# EFR32ZG23A020F512GM40 register map
Vendor: Silicon Labs; Series: EFR32; File version: B
Registers are 32-bit, read-write, reset 0x0 unless marked. A register's access mark holds for its fields unless they carry their own. Offsets are from the block's base; [hi:lo] are bit positions; {n}, {i} and the like mark numbered series; 'fields as' and 'values as' point back to an identical list.

## AGC_S — AGC_S Registers
Base 0xA800C000
Same registers: AGC_NS 0xB800C000
0x00 IPVERSION ro reset 0x2
0x04 EN
  [0] EN — Enable peripheral clock to this module
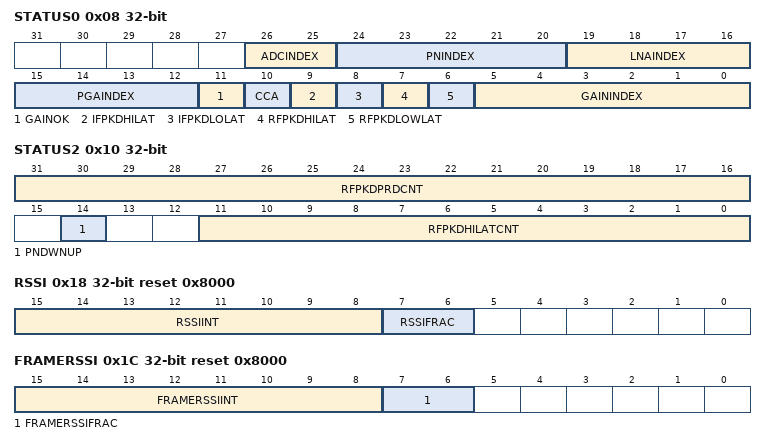
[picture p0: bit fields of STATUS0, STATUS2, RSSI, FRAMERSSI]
0x08 STATUS0 ro
  [26:25] ADCINDEX — ADC Attenuator INDEX
  [24:20] PNINDEX — PN GAIN INDEX
  [19:16] LNAINDEX — LNA GAIN INDEX
  [15:12] PGAINDEX — PGA GAIN INDEX
  [11] GAINOK
  [10] CCA — Clear Channel Assessment
  [9] IFPKDHILAT — IFPKD Hi threshold pass Latch
  [8] IFPKDLOLAT — IFPKD Lo threshold pass Latch
  [7] RFPKDHILAT — RFPKD hi Latch
  [6] RFPKDLOWLAT — RFPKD low Latch
  [5:0] GAININDEX — Gain Table Index
0x0C STATUS1 ro
  [29:18] RFPKDLOWLATCNT — RF PKD Low Latch CNT
0x10 STATUS2 ro
  [31:16] RFPKDPRDCNT — RF PKD PERIOD CNT
  [14] PNDWNUP — Allow PN GAIN UP
  [11:0] RFPKDHILATCNT — RF PKD HI Latch CNT
0x18 RSSI ro reset 0x8000
  [15:8] RSSIINT — RSSI integer part
  [7:6] RSSIFRAC — RSSI fractional part
0x1C FRAMERSSI ro reset 0x8000
  [15:8] FRAMERSSIINT — FRAMERSSI integer part
  [7:6] FRAMERSSIFRAC — FRAMERSSI fractional part
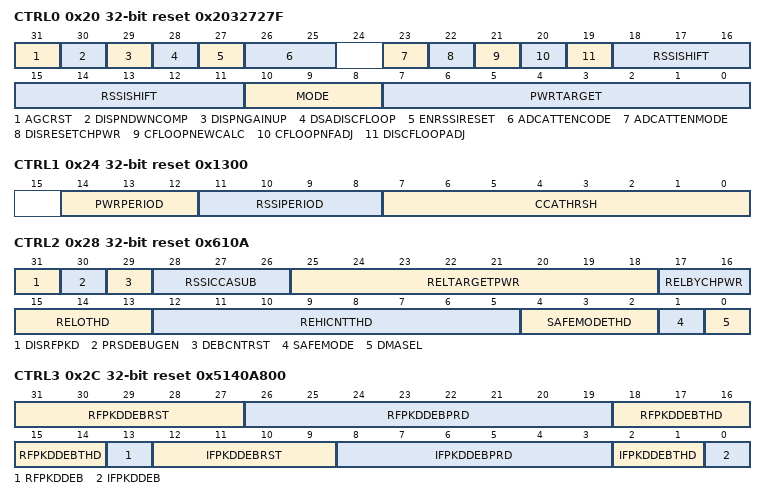
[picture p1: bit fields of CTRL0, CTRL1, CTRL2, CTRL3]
0x20 CTRL0 reset 0x2032727F
  [31] AGCRST — AGC reset
  [30] DISPNDWNCOMP — Disable PN gain decrease compensation
  [29] DISPNGAINUP — Disable PN gain increase
  [28] DSADISCFLOOP — Disable channel filter loop
  [27] ENRSSIRESET — Enables reset of RSSI and CCA
  [26:25] ADCATTENCODE — ADC Attenuator code
  [23] ADCATTENMODE — ADC Attenuator mode
    0=DISABLE (ADC attenuator back-off will not be done by AGC); 1=NOTMAXGAIN (ADC attenuator is backed-off if rxgain is NOT MAXGAIN)
  [22] DISRESETCHPWR — Disable Reset of CHPWR
  [21] CFLOOPNEWCALC — Enable new wanted gain calculation in SL
  [20] CFLOOPNFADJ — Enable NF correction term in SL
  [19] DISCFLOOPADJ — Disable gain adjustment by CFLOOP
  [18:11] RSSISHIFT
  [10:8] MODE
    0=CONT (AGC loop is adjusting gain continuously.); 1=LOCKPREDET (Gain is locked once a preamble is detected.); 2=LOCKFRAMEDET (Gain is locked once a sync word is detected.); 3=LOCKDSA (Gain is locked once DSA is detected.)
  [7:0] PWRTARGET — Power Target
0x24 CTRL1 reset 0x1300
  [14:12] PWRPERIOD — AGC measure period
  [11:8] RSSIPERIOD — RSSI measure period
  [7:0] CCATHRSH — Clear Channel Assessment (CCA) Threshold
0x28 CTRL2 reset 0x610A
  [31] DISRFPKD — Disable RF PEAKDET
  [30] PRSDEBUGEN — PRS Debug Enable
  [29] DEBCNTRST — Debonce CNT Reset MODE
  [28:26] RSSICCASUB — RSSI CCA sub windows
  [25:18] RELTARGETPWR — Safe Mode Release Power Target
  [17:16] RELBYCHPWR — Safe mode release mode
    0=LO_CNT (Increment counter if IFPKD_LO_LAT signal is not set.); 1=PWR (Increment counter if channel power is below RELTARGETPWR.); 2=LO_CNT_PWR (Increment if either LO_CNT or PWR.); 3=LO_CNT_AND_PWR (Increment if both LO_CNT and PWR.)
  [15:13] RELOTHD — Exit threshold based on Release Counter
  [12:5] REHICNTTHD — Exit threshold based on HICNT
  [4:2] SAFEMODETHD — Enter threshold
  [1] SAFEMODE — AGC safe mode
  [0] DMASEL — DMA select
    0=RSSI; 1=GAIN
0x2C CTRL3 reset 0x5140A800
  [31:27] RFPKDDEBRST — RFPKD_LAT debounce reset delay
  [26:19] RFPKDDEBPRD — RF PEAKDET debance period
  [18:14] RFPKDDEBTHD — RF PEAKDET debance thrshold
  [13] RFPKDDEB — RF PEAKDET debounce mode enable
  [12:9] IFPKDDEBRST — IF PEAKDET debounce period
  [8:3] IFPKDDEBPRD — IF PEAKDET debance period
  [2:1] IFPKDDEBTHD — IF PEAKDET debance thrshold
  [0] IFPKDDEB — IF PEAKDET debounce mode enable
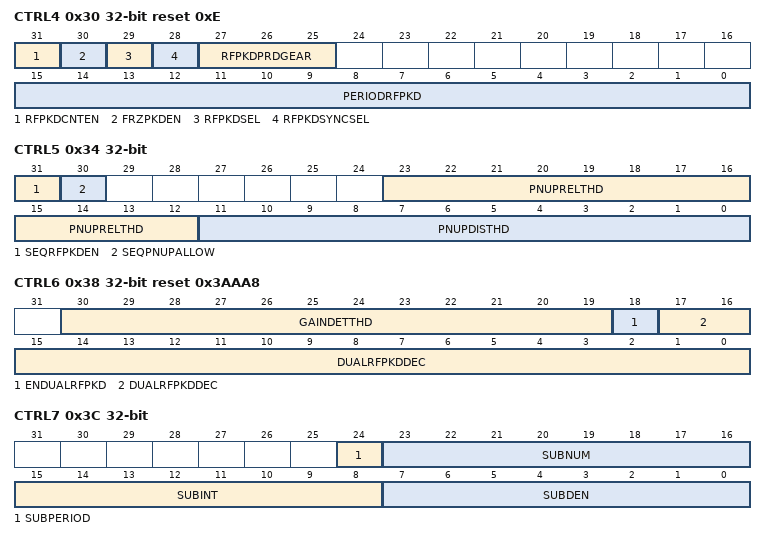
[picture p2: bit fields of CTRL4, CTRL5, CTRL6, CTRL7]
0x30 CTRL4 reset 0xE
  [31] RFPKDCNTEN — Counter-based RFPKD Enable
  [30] FRZPKDEN — PKD Freeze Enable
  [29] RFPKDSEL — RF PKD OUTPUT SELECT
  [28] RFPKDSYNCSEL — SYNC RF PKD OUTPUT SELECT
  [27:25] RFPKDPRDGEAR — RFPKD Period Gear
  [15:0] PERIODRFPKD — RFPKD trigger measure period
0x34 CTRL5
  [31] SEQRFPKDEN — SEQ-based RFPKD Enable
  [30] SEQPNUPALLOW — SEQ Set PN GAIN UP ALLOW
  [23:12] PNUPRELTHD — Enable PN GAIN increase THD
  [11:0] PNUPDISTHD — Disable PN GAIN increase THD
0x38 CTRL6 reset 0x3AAA8
  [30:19] GAINDETTHD — Threshold for gain aligned interrupt
  [18] ENDUALRFPKD — Enable dual RFPKD
  [17:0] DUALRFPKDDEC — Decoding matrix for dualrfpkd logic
0x3C CTRL7
  [24] SUBPERIOD
  [23:16] SUBNUM — Subperiod numerator
  [15:8] SUBINT — Subperiod integer
  [7:0] SUBDEN — Subperiod denominator
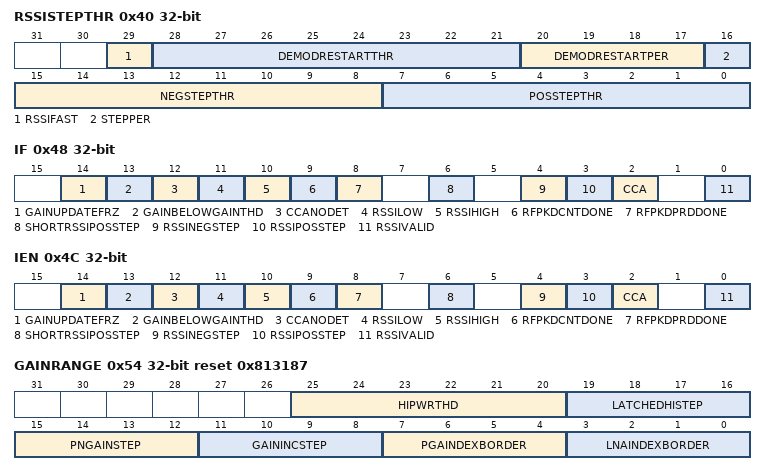
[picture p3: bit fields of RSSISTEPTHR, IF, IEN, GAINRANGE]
0x40 RSSISTEPTHR
  [29] RSSIFAST — RSSI fast startup
  [28:21] DEMODRESTARTTHR — Demodulator Restart Threshold
  [20:17] DEMODRESTARTPER — Demodulator Restart Period
  [16] STEPPER — Step Period
  [15:8] NEGSTEPTHR — Negative Step Threshold
  [7:0] POSSTEPTHR — Positive Step Threshold
0x48 IF
  [14] GAINUPDATEFRZ — AGC gain update frozen int
  [13] GAINBELOWGAINTHD — agc gain above threshold int
  [12] CCANODET — CCA Not Detected
  [11] RSSILOW — RSSI low detected
  [10] RSSIHIGH — RSSI high detected
  [9] RFPKDCNTDONE — RF PKD pulse CNT TOMEOUT
  [8] RFPKDPRDDONE — RF PKD PERIOD CNT TOMEOUT
  [6] SHORTRSSIPOSSTEP — Short-term Positive RSSI Step Detected
  [4] RSSINEGSTEP — Negative RSSI Step Detected
  [3] RSSIPOSSTEP — Positive RSSI Step Detected
  [2] CCA — Clear Channel Assessment
  [0] RSSIVALID — RSSI Value is Valid
0x4C IEN
  [14] GAINUPDATEFRZ — AGC gain update frozen int Enable
  [13] GAINBELOWGAINTHD — GAINBELOWGAINTHD Interrupt Enable
  [12] CCANODET — CCANODET Interrupt Enable
  [11] RSSILOW — RSSILOW Interrupt Enable
  [10] RSSIHIGH — RSSIHIGH Interrupt Enable
  [9] RFPKDCNTDONE — RF PKD pulse CNT Interrupt Enable
  [8] RFPKDPRDDONE — RF PKD PERIOD CNT Interrupt Enable
  [6] SHORTRSSIPOSSTEP — SHORTRSSIPOSSTEP Interrupt Enable
  [4] RSSINEGSTEP — RSSINEGSTEP Interrupt Enable
  [3] RSSIPOSSTEP — RSSIPOSSTEP Interrupt Enable
  [2] CCA — CCA Interrupt Enable
  [0] RSSIVALID — RSSIVALID Interrupt Enable
0x54 GAINRANGE reset 0x813187
  [25:20] HIPWRTHD — High power detect thrshold
  [19:16] LATCHEDHISTEP — Ltached Hi step size
  [15:12] PNGAINSTEP — PN Gain Step size
  [11:8] GAININCSTEP — AGC gain increase step size
  [7:4] PGAINDEXBORDER — PGA gain border
  [3:0] LNAINDEXBORDER — LNA gain border
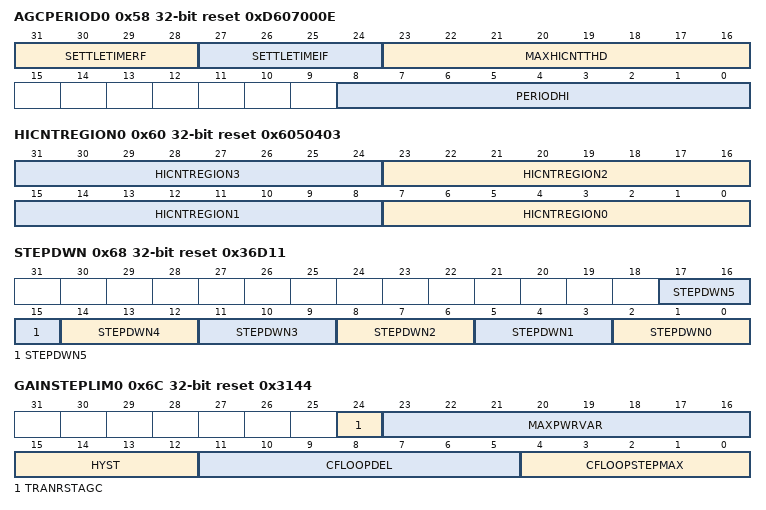
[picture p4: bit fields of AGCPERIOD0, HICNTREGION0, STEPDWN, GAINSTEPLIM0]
0x58 AGCPERIOD0 reset 0xD607000E
  [31:28] SETTLETIMERF — RF peak Detector settling time
  [27:24] SETTLETIMEIF — IF peak Detector settling time
  [23:16] MAXHICNTTHD — max hi-countrer threshold
  [8:0] PERIODHI — AGC measure period hi
0x5C AGCPERIOD1 reset 0x37
  [31:0] PERIODLOW — AGC IF period low th
0x60 HICNTREGION0 reset 0x6050403
  [8n+7:8n] HICNTREGION{n} (n=0..3) — AGC HICNT to step size map region {n}
0x64 HICNTREGION1 reset 0x8
  [7:0] HICNTREGION4 — AGC HICNT to step size map region 4
0x68 STEPDWN reset 0x36D11
  [3n+2:3n] STEPDWN{n} (n=0..5) — AGC gain step size {n}
0x6C GAINSTEPLIM0 reset 0x3144
  [24] TRANRSTAGC — power transient detector Reset AGC
  [23:16] MAXPWRVAR — Maximum Power Variation
  [15:12] HYST — Hysteresis
  [11:5] CFLOOPDEL — Channel Filter Loop Delay
  [4:0] CFLOOPSTEPMAX — Maximum step in slow loop
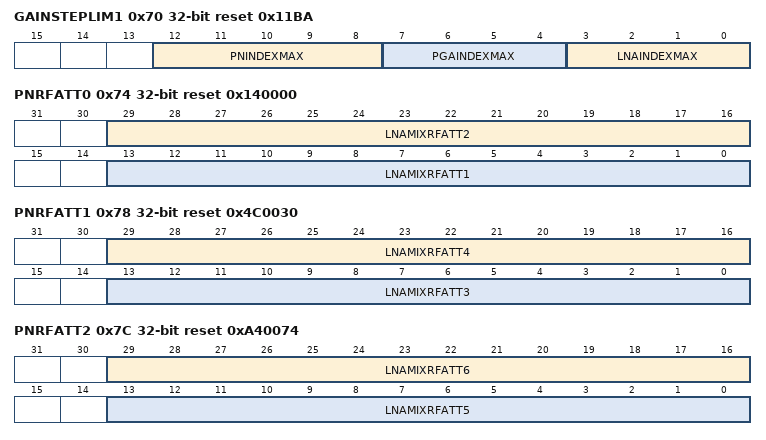
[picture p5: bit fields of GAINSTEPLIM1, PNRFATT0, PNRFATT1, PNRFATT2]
0x70 GAINSTEPLIM1 reset 0x11BA
  [12:8] PNINDEXMAX — MAX PN INDEX
  [7:4] PGAINDEXMAX — MAX LNA INDEX
  [3:0] LNAINDEXMAX — MAX LNA INDEX
0x74 PNRFATT0 reset 0x140000
  [29:16] LNAMIXRFATT2 — PN RF attenuation code for index 2
  [13:0] LNAMIXRFATT1 — PN RF attenuation code for index 1
0x78 PNRFATT1 reset 0x4C0030
  [29:16] LNAMIXRFATT4 — PN RF attenuation code for index 4
  [13:0] LNAMIXRFATT3 — PN RF attenuation code for index 3
0x7C PNRFATT2 reset 0xA40074
  [29:16] LNAMIXRFATT6 — PN RF attenuation code for index 6
  [13:0] LNAMIXRFATT5 — PN RF attenuation code for index 5
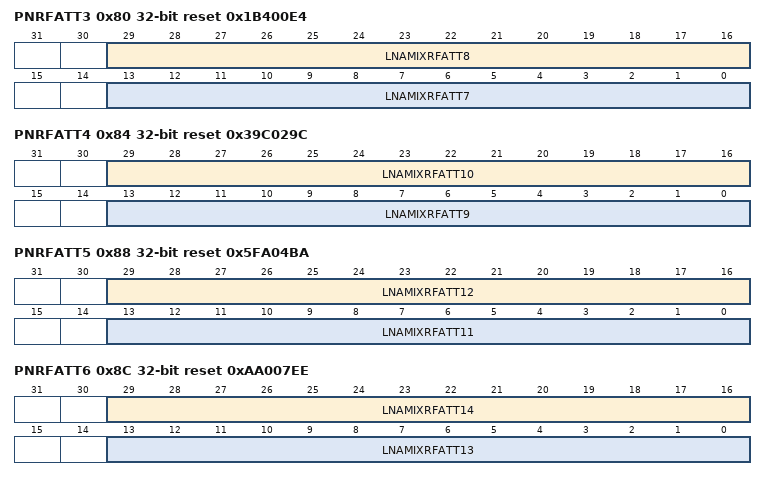
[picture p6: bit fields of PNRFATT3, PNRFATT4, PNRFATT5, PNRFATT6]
0x80 PNRFATT3 reset 0x1B400E4
  [29:16] LNAMIXRFATT8 — PN RF attenuation code for index 8
  [13:0] LNAMIXRFATT7 — PN RF attenuation code for index 7
0x84 PNRFATT4 reset 0x39C029C
  [29:16] LNAMIXRFATT10 — PN RF attenuation code for index 10
  [13:0] LNAMIXRFATT9 — PN RF attenuation code for index 9
0x88 PNRFATT5 reset 0x5FA04BA
  [29:16] LNAMIXRFATT12 — PN RF attenuation code for index 12
  [13:0] LNAMIXRFATT11 — PN RF attenuation code for index 11
0x8C PNRFATT6 reset 0xAA007EE
  [29:16] LNAMIXRFATT14 — PN RF attenuation code for index 14
  [13:0] LNAMIXRFATT13 — PN RF attenuation code for index 13
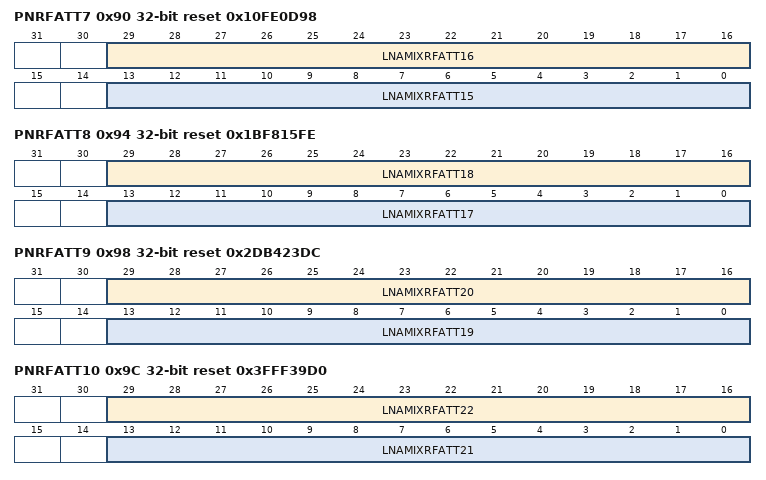
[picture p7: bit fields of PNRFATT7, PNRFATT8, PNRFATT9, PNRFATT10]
0x90 PNRFATT7 reset 0x10FE0D98
  [29:16] LNAMIXRFATT16 — PN RF attenuation code for index 16
  [13:0] LNAMIXRFATT15 — PN RF attenuation code for index 15
0x94 PNRFATT8 reset 0x1BF815FE
  [29:16] LNAMIXRFATT18 — PN RF attenuation code for index 18
  [13:0] LNAMIXRFATT17 — PN RF attenuation code for index 17
0x98 PNRFATT9 reset 0x2DB423DC
  [29:16] LNAMIXRFATT20 — PN RF attenuation code for index 20
  [13:0] LNAMIXRFATT19 — PN RF attenuation code for index 19
0x9C PNRFATT10 reset 0x3FFF39D0
  [29:16] LNAMIXRFATT22 — PN RF attenuation code for index 22
  [13:0] LNAMIXRFATT21 — PN RF attenuation code for index 21
0xA0 PNRFATT11 reset 0x3FFF
  [13:0] LNAMIXRFATT23 — PN RF attenuation code for index 23
0xA4 PNRFATTALT reset 0x3FFF
  [13:0] LNAMIXRFATTALT — PN RF attenuation code for index 21
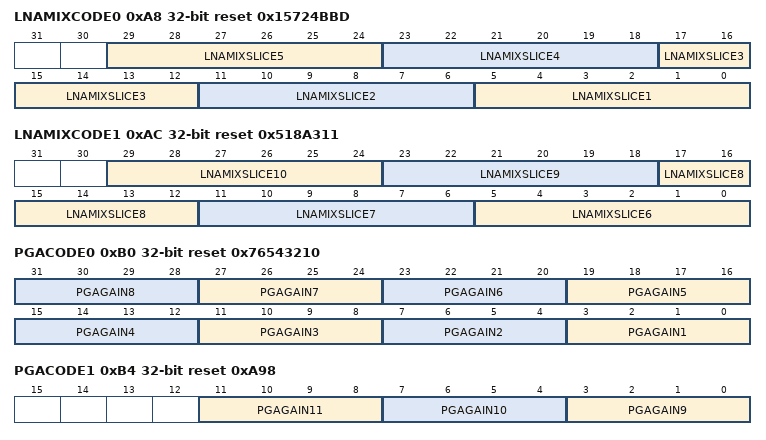
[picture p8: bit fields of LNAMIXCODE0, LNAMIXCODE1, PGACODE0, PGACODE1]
0xA8 LNAMIXCODE0 reset 0x15724BBD
  [6n-1:6n-6] LNAMIXSLICE{n} (n=1..5) — LNA/MIX slice code for index {n}
0xAC LNAMIXCODE1 reset 0x518A311
  [6n-31:6n-36] LNAMIXSLICE{n} (n=6..10) — LNA/MIX slice code for index {n}
0xB0 PGACODE0 reset 0x76543210
  [4n-1:4n-4] PGAGAIN{n} (n=1..8) — PGA GAIN code for index {n}
0xB4 PGACODE1 reset 0xA98
  [11:8] PGAGAIN11 — PGA GAIN code for index 11
  [7:4] PGAGAIN10 — PGA GAIN code for index 10
  [3:0] PGAGAIN9 — PGA GAIN code for index 9
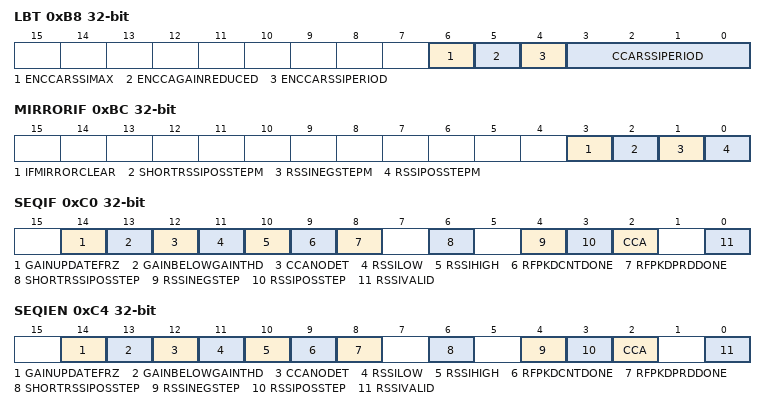
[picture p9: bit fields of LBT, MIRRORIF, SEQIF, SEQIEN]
0xB8 LBT
  [6] ENCCARSSIMAX — Use RSSIMAX to indicate CCA
  [5] ENCCAGAINREDUCED — CCA gain reduced
  [4] ENCCARSSIPERIOD — RSSI PERIOD during CCA measurements
  [3:0] CCARSSIPERIOD — RSSI Period during CCA measurements
0xBC MIRRORIF
  [3] IFMIRRORCLEAR — Clear bit for the AGC IF MIRROR Register
  [2] SHORTRSSIPOSSTEPM ro — Short-term Positive RSSI Step Detected
  [1] RSSINEGSTEPM ro — Negative RSSI Step Detected
  [0] RSSIPOSSTEPM ro — Positive RSSI Step Detected
0xC0 SEQIF
  fields as IF
0xC4 SEQIEN
  fields as IEN
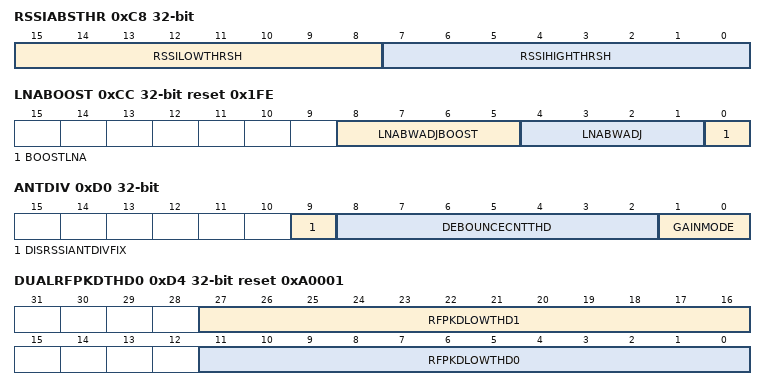
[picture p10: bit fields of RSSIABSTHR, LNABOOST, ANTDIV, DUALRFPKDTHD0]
0xC8 RSSIABSTHR
  [15:8] RSSILOWTHRSH — RSSI Low Threshold
  [7:0] RSSIHIGHTHRSH — RSSI High Threshold
0xCC LNABOOST reset 0x1FE
  [8:5] LNABWADJBOOST — LNA BW ADJUST
  [4:1] LNABWADJ — LNA BW ADJUST
  [0] BOOSTLNA — LNA GAIN BOOST mode
0xD0 ANTDIV
  [9] DISRSSIANTDIVFIX — Disables RSSI fix for antenna diversity
  [8:2] DEBOUNCECNTTHD — Gain restore debounce timer threshold
  [1:0] GAINMODE — Antenna gain restore mode
    0=DISABLE (Gain restore feature disabled); 1=SINGLE_PACKET (Gain restore enabled. The stored gain will be cleared when current RX off.); 2=ALWAYS (Gain restore enabled. The stored gain will be kept across packets.)
0xD4 DUALRFPKDTHD0 reset 0xA0001
  [27:16] RFPKDLOWTHD1 — low rfpkd threshold 1
  [11:0] RFPKDLOWTHD0 — low rfpkd threshold 0
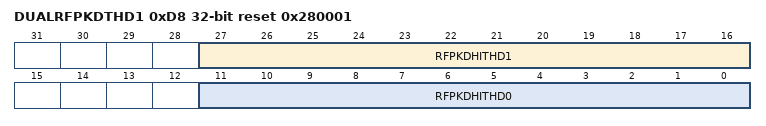
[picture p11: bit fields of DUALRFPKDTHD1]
0xD8 DUALRFPKDTHD1 reset 0x280001
  [27:16] RFPKDHITHD1 — low rfpkd threshold 1
  [11:0] RFPKDHITHD0 — low rfpkd threshold 0
0xDC SPARE
  [7:0] SPAREREG — Spare reg for ECOs
